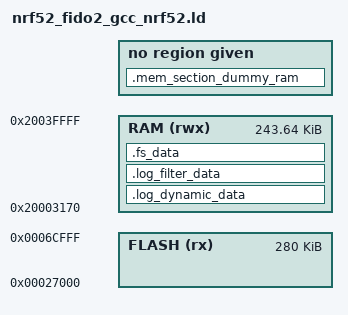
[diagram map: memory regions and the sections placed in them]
/* Linker script to configure memory regions. */

SEARCH_DIR(.)
GROUP(-lgcc -lc -lnosys)

/*MEMORY
{*/
/*  FLASH (rx) : ORIGIN = 0x1000, LENGTH = 0xff000  0x46000*/
/*  FLASH (rx) : ORIGIN = 0x27000, LENGTH = 0xd9000 */
/*  FLASH (rx) : ORIGIN = 0x27000, LENGTH = 0xd9000 */
/*  RAM (rwx) :  ORIGIN = 0x20000600, LENGTH = 0x3fa00 */
/*  RAM (rwx) :  ORIGIN = 0x20000008, LENGTH = 0x3fff8*/
/*} */

MEMORY
{
  FLASH (rx) : ORIGIN = 0x27000, LENGTH = 0x46000
  RAM (rwx) :  ORIGIN = 0x20003170, LENGTH = 0x3CE90
}

/*SECTIONS*/
/*{*/
/*}*/

SECTIONS
{
  . = ALIGN(4);
  .mem_section_dummy_ram :
  {
  }
  .log_dynamic_data :
  {
    PROVIDE(__start_log_dynamic_data = .);
    KEEP(*(SORT(.log_dynamic_data*)))
    PROVIDE(__stop_log_dynamic_data = .);
  } > RAM
  .log_filter_data :
  {
    PROVIDE(__start_log_filter_data = .);
    KEEP(*(SORT(.log_filter_data*)))
    PROVIDE(__stop_log_filter_data = .);
  } > RAM
  .fs_data :
  {
    PROVIDE(__start_fs_data = .);
    KEEP(*(.fs_data))
    PROVIDE(__stop_fs_data = .);
  } > RAM

} INSERT AFTER .data;

SECTIONS
{
  .mem_section_dummy_rom :
  {
  }
  .sdh_soc_observers :
  {
    PROVIDE(__start_sdh_soc_observers = .);
    KEEP(*(SORT(.sdh_soc_observers*)))
    PROVIDE(__stop_sdh_soc_observers = .);
  } > FLASH
  .sdh_state_observers :
  {
    PROVIDE(__start_sdh_state_observers = .);
    KEEP(*(SORT(.sdh_state_observers*)))
    PROVIDE(__stop_sdh_state_observers = .);
  } > FLASH
  .sdh_stack_observers :
  {
    PROVIDE(__start_sdh_stack_observers = .);
    KEEP(*(SORT(.sdh_stack_observers*)))
    PROVIDE(__stop_sdh_stack_observers = .);
  } > FLASH
  .sdh_req_observers :
  {
    PROVIDE(__start_sdh_req_observers = .);
    KEEP(*(SORT(.sdh_req_observers*)))
    PROVIDE(__stop_sdh_req_observers = .);
  } > FLASH
    .nrf_queue :
  {
    PROVIDE(__start_nrf_queue = .);
    KEEP(*(.nrf_queue))
    PROVIDE(__stop_nrf_queue = .);
  } > FLASH
    .nrf_balloc :
  {
    PROVIDE(__start_nrf_balloc = .);
    KEEP(*(.nrf_balloc))
    PROVIDE(__stop_nrf_balloc = .);
  } > FLASH
    .cli_command :
  {
    PROVIDE(__start_cli_command = .);
    KEEP(*(.cli_command))
    PROVIDE(__stop_cli_command = .);
  } > FLASH
  .crypto_data :
  {
    PROVIDE(__start_crypto_data = .);
    KEEP(*(SORT(.crypto_data*)))
    PROVIDE(__stop_crypto_data = .);
  } > FLASH
  .pwr_mgmt_data :
  {
    PROVIDE(__start_pwr_mgmt_data = .);
    KEEP(*(SORT(.pwr_mgmt_data*)))
    PROVIDE(__stop_pwr_mgmt_data = .);
  } > FLASH
  .log_const_data :
  {
    PROVIDE(__start_log_const_data = .);
    KEEP(*(SORT(.log_const_data*)))
    PROVIDE(__stop_log_const_data = .);
  } > FLASH
  .sdh_ble_observers :
  {
    PROVIDE(__start_sdh_ble_observers = .);
    KEEP(*(SORT(.sdh_ble_observers*)))
    PROVIDE(__stop_sdh_ble_observers = .);
  } > FLASH
  .log_backends :
  {
    PROVIDE(__start_log_backends = .);
    KEEP(*(SORT(.log_backends*)))
    PROVIDE(__stop_log_backends = .);
  } > FLASH

} INSERT AFTER .text

/*
SECTIONS
{
  .mem_section_dummy_rom :
  {
  }
  .crypto_data :
  {
    PROVIDE(__start_crypto_data = .);
    KEEP(*(SORT(.crypto_data*)))
    PROVIDE(__stop_crypto_data = .);
  } > FLASH
  .sdh_state_observers :
  {
    PROVIDE(__start_sdh_state_observers = .);
    KEEP(*(SORT(.sdh_state_observers*)))
    PROVIDE(__stop_sdh_state_observers = .);
  } > FLASH
  .sdh_stack_observers :
  {
    PROVIDE(__start_sdh_stack_observers = .);
    KEEP(*(SORT(.sdh_stack_observers*)))
    PROVIDE(__stop_sdh_stack_observers = .);
  } > FLASH
  .sdh_req_observers :
  {
    PROVIDE(__start_sdh_req_observers = .);
    KEEP(*(SORT(.sdh_req_observers*)))
    PROVIDE(__stop_sdh_req_observers = .);
  } > FLASH
  .nrf_queue :
  {
    PROVIDE(__start_nrf_queue = .);
    KEEP(*(.nrf_queue))
    PROVIDE(__stop_nrf_queue = .);
  } > FLASH
  .log_const_data :
  {
    PROVIDE(__start_log_const_data = .);
    KEEP(*(SORT(.log_const_data*)))
    PROVIDE(__stop_log_const_data = .);
  } > FLASH
  .log_backends :
  {
    PROVIDE(__start_log_backends = .);
    KEEP(*(SORT(.log_backends*)))
    PROVIDE(__stop_log_backends = .);
  } > FLASH
  .pwr_mgmt_data :
  {
    PROVIDE(__start_pwr_mgmt_data = .);
    KEEP(*(SORT(.pwr_mgmt_data*)))
    PROVIDE(__stop_pwr_mgmt_data = .);
  } > FLASH
  .nrf_balloc :
  {
    PROVIDE(__start_nrf_balloc = .);
    KEEP(*(.nrf_balloc))
    PROVIDE(__stop_nrf_balloc = .);
  } > FLASH

} INSERT AFTER .text
*/


INCLUDE "nrf_common.ld"
